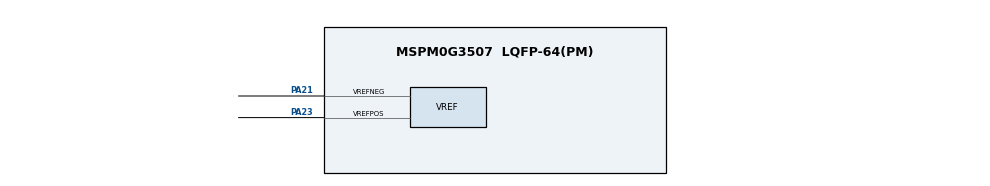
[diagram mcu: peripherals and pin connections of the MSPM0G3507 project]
/**
 * These arguments were used when this file was generated. They will be automatically applied on subsequent loads
 * via the GUI or CLI. Run CLI with '--help' for additional information on how to override these arguments.
 */
//@cliArgs --device "MSPM0G350X" --package "LQFP-64(PM)" --part "Default"
//@v2CliArgs --device "MSPM0G3507" --package "LQFP-64(PM)"
// @cliArgs --board /ti/boards/LP_MSPM0G3507 --rtos nortos

/**
 * Import the modules used in this configuration.
 */
const DAC12  = scripting.addModule("/ti/driverlib/DAC12");
const PWM    = scripting.addModule("/ti/driverlib/PWM", {}, false);
const PWM1   = PWM.addInstance();
const SYSCTL = scripting.addModule("/ti/driverlib/SYSCTL");
const VREF   = scripting.addModule("/ti/driverlib/VREF");

/**
 * Write custom configuration values to the imported modules.
 */
const gate8  = system.clockTree["MFPCLKGATE"];
gate8.enable = true;

DAC12.dacOutputPinEn = true;
DAC12.dacAmplifier   = "ON";
DAC12.dacPosVREF     = "VEREFP";
DAC12.dacNegVREF     = "VEREFN";

/*
 * BRIDGE_PINS — PA8 and PA22 are configured as GPIO outputs at boot.
 *   PA8  (PINCM19) -> Q2b gate (dummy path): boot HIGH = dummy ON (safe)
 *   PA22 (PINCM47) -> Q2a gate (laser path): boot LOW  = laser OFF (safe)
 *
 * laser_pwm_control.c switches these pins between GPIO and TIMA0 peripheral
 * function at runtime.  SysConfig only sees the GPIO role; the peripheral
 * function codes are written directly to the IOMUX registers in application code.
 */
const GPIO  = scripting.addModule("/ti/driverlib/GPIO", {}, false);
const GPIO1 = GPIO.addInstance();
GPIO1.$name                          = "BRIDGE_DUMMY";
GPIO1.associatedPins[0].$name        = "DUMMY";
GPIO1.associatedPins[0].assignedPort = "PORTA";
GPIO1.associatedPins[0].assignedPin  = "8";
GPIO1.associatedPins[0].initialValue = "SET";

const GPIO2 = GPIO.addInstance();
GPIO2.$name                          = "BRIDGE_LASER";
GPIO2.associatedPins[0].$name        = "LASER";
GPIO2.associatedPins[0].assignedPort = "PORTA";
GPIO2.associatedPins[0].assignedPin  = "22";
GPIO2.associatedPins[0].initialValue = "CLEARED";

/*
 * PWM_0 — TIMA0 configured for 100 kHz edge-aligned PWM with shadow load.
 *   Clock: BUSCLK = 32 MHz, prescale = 1 -> 32 MHz timer clock
 *   Period: 320 counts -> 100 kHz
 *   Laser duty = (320 - ccValue) / 320
 *
 * No pin assignments here — PA8/PA22 are routed to TIMA0 at runtime by
 * laser_pwm_control.c, not by the generated GPIO init.
 */
PWM1.$name                           = "PWM_0";
PWM1.ccIndex                         = [0];
PWM1.clockSource                     = "BUSCLK";
PWM1.clockPrescale                   = 1;
PWM1.timerCount                      = 319;
PWM1.pwmMode                         = "EDGE_ALIGN";
PWM1.enableShadowLoad                = true;
PWM1.peripheral.$assign              = "TIMA0";
PWM1.PWM_CHANNEL_0.$name             = "ti_driverlib_pwm_PWMTimerCC0";
PWM1.PWM_CHANNEL_0.ccValue           = 319;
PWM1.PWM_CHANNEL_0.shadowUpdateMode  = "ZERO_EVT";

const Board = scripting.addModule("/ti/driverlib/Board", {}, false);

SYSCTL.MFPCLKEn    = true;
SYSCTL.forceDefaultClkConfig = true;
SYSCTL.clockTreeEn  = true;

VREF.basicVrefPins                 = "VREF+-";
VREF.basicIntVolt                  = "DL_VREF_BUFCONFIG_OUTPUT_2_5V";
VREF.checkVREFReady                = true;
VREF.advClockConfigEnable          = true;
VREF.advClkSrc                     = "DL_VREF_CLOCK_BUSCLK";
VREF.peripheral.$assign            = "VREF";
VREF.peripheral.vrefPosPin.$assign = "PA23";
VREF.peripheral.vrefNegPin.$assign = "PA21";
